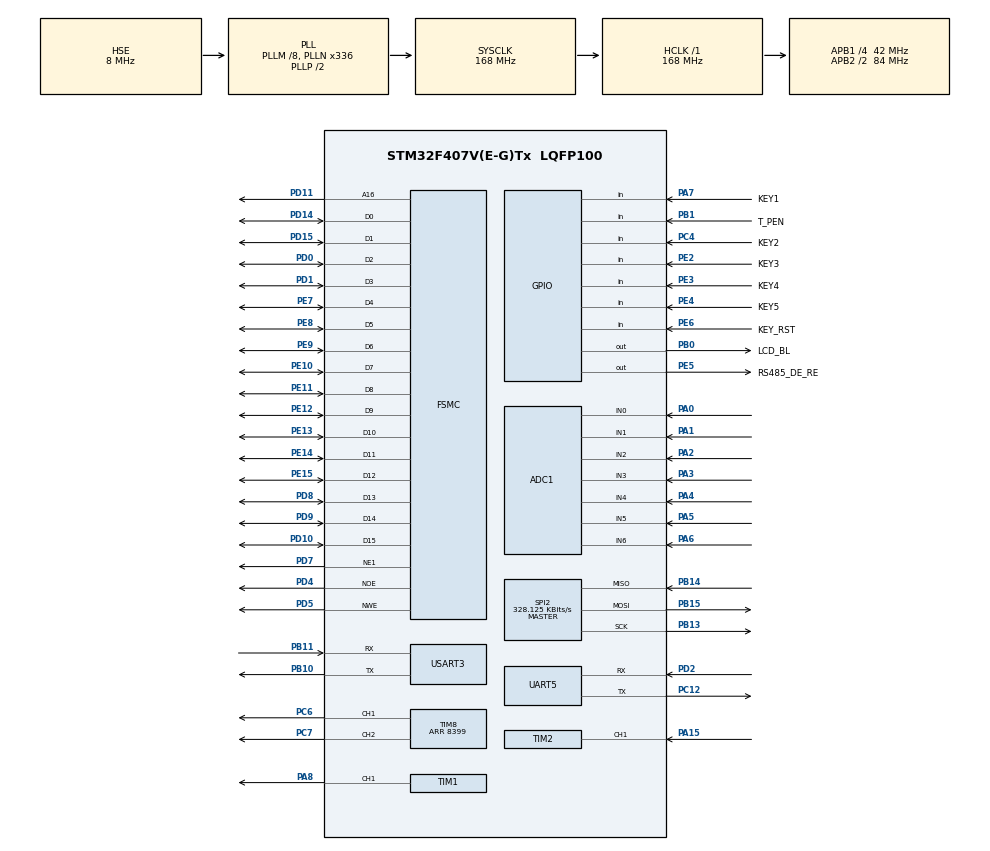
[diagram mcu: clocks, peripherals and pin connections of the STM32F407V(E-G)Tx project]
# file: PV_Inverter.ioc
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ADC1.Channel-12\#ChannelRegularConversion=ADC_CHANNEL_1
ADC1.Channel-13\#ChannelRegularConversion=ADC_CHANNEL_2
ADC1.Channel-14\#ChannelRegularConversion=ADC_CHANNEL_3
ADC1.Channel-15\#ChannelRegularConversion=ADC_CHANNEL_4
ADC1.Channel-16\#ChannelRegularConversion=ADC_CHANNEL_5
ADC1.Channel-17\#ChannelRegularConversion=ADC_CHANNEL_6
ADC1.ContinuousConvMode=ENABLE
ADC1.DMAContinuousRequests=ENABLE
ADC1.NbrOfConversion=7
ADC1.NbrOfConversionFlag=1
ADC1.Rank-12\#ChannelRegularConversion=2
ADC1.Rank-13\#ChannelRegularConversion=3
ADC1.Rank-14\#ChannelRegularConversion=4
ADC1.Rank-15\#ChannelRegularConversion=5
ADC1.Rank-16\#ChannelRegularConversion=6
ADC1.Rank-17\#ChannelRegularConversion=7
ADC1.SamplingTime-0\#ChannelRegularConversion=ADC_SAMPLETIME_480CYCLES
ADC1.SamplingTime-12\#ChannelRegularConversion=ADC_SAMPLETIME_480CYCLES
ADC1.SamplingTime-13\#ChannelRegularConversion=ADC_SAMPLETIME_480CYCLES
ADC1.SamplingTime-14\#ChannelRegularConversion=ADC_SAMPLETIME_144CYCLES
ADC1.SamplingTime-15\#ChannelRegularConversion=ADC_SAMPLETIME_144CYCLES
ADC1.SamplingTime-16\#ChannelRegularConversion=ADC_SAMPLETIME_480CYCLES
ADC1.SamplingTime-17\#ChannelRegularConversion=ADC_SAMPLETIME_480CYCLES
ADC1.ScanConvMode=ENABLE
ADC1.master=1
Dma.ADC1.0.Direction=DMA_PERIPH_TO_MEMORY
Dma.ADC1.0.FIFOMode=DMA_FIFOMODE_DISABLE
Dma.ADC1.0.Instance=DMA2_Stream0
Dma.ADC1.0.MemDataAlignment=DMA_MDATAALIGN_HALFWORD
Dma.ADC1.0.MemInc=DMA_MINC_ENABLE
Dma.ADC1.0.Mode=DMA_CIRCULAR
Dma.ADC1.0.PeriphDataAlignment=DMA_PDATAALIGN_HALFWORD
Dma.ADC1.0.PeriphInc=DMA_PINC_DISABLE
Dma.ADC1.0.Priority=DMA_PRIORITY_HIGH
Dma.Request0=ADC1
FREERTOS.Tasks01=defaultTask,24,128,StartDefaultTask,Default,NULL,Dynamic,NULL,NULL
FSMC.BusTurnAroundDuration1=0
FSMC.DataSetupTime1=15
IWDG.Prescaler=IWDG_PRESCALER_64
IWDG.Reload=1250
Mcu.Family=STM32F4
Mcu.Name=STM32F407V(E-G)Tx
Mcu.Package=LQFP100
NVIC.DMA2_Stream0_IRQn=true\:5\:0\:false\:false\:true\:true\:false\:true\:true
NVIC.PriorityGroup=NVIC_PRIORITYGROUP_4
NVIC.TIM6_DAC_IRQn=true\:15\:0\:false\:false\:true\:false\:false\:true\:true
NVIC.TimeBase=TIM6_DAC_IRQn
NVIC.TimeBaseIP=TIM6
NVIC.UART5_IRQn=true\:5\:0\:false\:false\:true\:true\:true\:true\:true
NVIC.USART3_IRQn=true\:5\:0\:false\:false\:true\:true\:true\:true\:true
PA0-WKUP.Signal=ADCx_IN0
PA1.Signal=ADCx_IN1
PA13.Mode=Serial_Wire
PA13.Signal=SYS_JTMS-SWDIO
PA14.Mode=Serial_Wire
PA14.Signal=SYS_JTCK-SWCLK
PA15.Signal=S_TIM2_CH1_ETR
PA2.Signal=ADCx_IN2
PA3.Signal=ADCx_IN3
PA4.Signal=ADCx_IN4
PA5.Signal=ADCx_IN5
PA6.Signal=ADCx_IN6
PA7.GPIO_Label=KEY1
PA7.GPIO_PuPd=GPIO_PULLUP
PA7.Signal=GPIO_Input
PA8.Signal=S_TIM1_CH1
PB0.GPIO_Label=LCD_BL
PB0.PinState=GPIO_PIN_SET
PB0.Signal=GPIO_Output
PB1.GPIO_Label=T_PEN
PB1.GPIO_PuPd=GPIO_PULLUP
PB1.Signal=GPIO_Input
PB10.Mode=Asynchronous
PB10.Signal=USART3_TX
PB11.Mode=Asynchronous
PB11.Signal=USART3_RX
PB12.Signal=SPI2_NSS
PB13.Mode=Full_Duplex_Master
PB13.Signal=SPI2_SCK
PB14.Mode=Full_Duplex_Master
PB14.Signal=SPI2_MISO
PB15.Mode=Full_Duplex_Master
PB15.Signal=SPI2_MOSI
PC12.Mode=Asynchronous
PC12.Signal=UART5_TX
PC4.GPIO_Label=KEY2
PC4.GPIO_PuPd=GPIO_PULLUP
PC4.Signal=GPIO_Input
PC6.Signal=S_TIM8_CH1
PC7.Signal=S_TIM8_CH2
PD0.Mode=16b-d1
PD0.Signal=FSMC_D2
PD1.Mode=16b-d1
PD1.Signal=FSMC_D3
PD10.Mode=16b-d1
PD10.Signal=FSMC_D15
PD11.Mode=A16_1
PD11.Signal=FSMC_A16
PD14.Mode=16b-d1
PD14.Signal=FSMC_D0
PD15.Mode=16b-d1
PD15.Signal=FSMC_D1
PD2.Mode=Asynchronous
PD2.Signal=UART5_RX
PD4.Mode=Lcd1
PD4.Signal=FSMC_NOE
PD5.Mode=Lcd1
PD5.Signal=FSMC_NWE
PD7.Mode=NorPsramChipSelect1_1
PD7.Signal=FSMC_NE1
PD8.Mode=16b-d1
PD8.Signal=FSMC_D13
PD9.Mode=16b-d1
PD9.Signal=FSMC_D14
PE10.Mode=16b-d1
PE10.Signal=FSMC_D7
PE11.Mode=16b-d1
PE11.Signal=FSMC_D8
PE12.Mode=16b-d1
PE12.Signal=FSMC_D9
PE13.Mode=16b-d1
PE13.Signal=FSMC_D10
PE14.Mode=16b-d1
PE14.Signal=FSMC_D11
PE15.Mode=16b-d1
PE15.Signal=FSMC_D12
PE2.GPIO_Label=KEY3
PE2.GPIO_PuPd=GPIO_PULLUP
PE2.Signal=GPIO_Input
PE3.GPIO_Label=KEY4
PE3.GPIO_PuPd=GPIO_PULLUP
PE3.Signal=GPIO_Input
PE4.GPIO_Label=KEY5
PE4.GPIO_PuPd=GPIO_PULLUP
PE4.Signal=GPIO_Input
PE5.GPIO_Label=RS485_DE_RE
PE5.Signal=GPIO_Output
PE6.GPIO_Label=KEY_RST
PE6.GPIO_PuPd=GPIO_PULLUP
PE6.Signal=GPIO_Input
PE7.Mode=16b-d1
PE7.Signal=FSMC_D4
PE8.Mode=16b-d1
PE8.Signal=FSMC_D5
PE9.Mode=16b-d1
PE9.Signal=FSMC_D6
PH0-OSC_IN.Mode=HSE-External-Oscillator
PH0-OSC_IN.Signal=RCC_OSC_IN
PH1-OSC_OUT.Mode=HSE-External-Oscillator
PH1-OSC_OUT.Signal=RCC_OSC_OUT
ProjectManager.HeapSize=0x200
ProjectManager.StackSize=0x400
ProjectManager.TargetToolchain=MDK-ARM V5.32
RCC.48MHZClocksFreq_Value=84000000
RCC.AHBFreq_Value=168000000
RCC.APB1CLKDivider=RCC_HCLK_DIV4
RCC.APB1Freq_Value=42000000
RCC.APB1TimFreq_Value=84000000
RCC.APB2CLKDivider=RCC_HCLK_DIV2
RCC.APB2Freq_Value=84000000
RCC.APB2TimFreq_Value=168000000
RCC.CortexFreq_Value=168000000
RCC.HCLKFreq_Value=168000000
RCC.HSE_VALUE=8000000
RCC.HSI_VALUE=16000000
RCC.LSE_VALUE=32768
RCC.PLLM=8
RCC.PLLN=336
RCC.PLLSourceVirtual=RCC_PLLSOURCE_HSE
RCC.SYSCLKFreq_VALUE=168000000
RCC.SYSCLKSource=RCC_SYSCLKSOURCE_PLLCLK
RCC.VCOOutputFreq_Value=336000000
SH.ADCx_IN0.0=ADC1_IN0,IN0
SH.ADCx_IN1.0=ADC1_IN1,IN1
SH.ADCx_IN2.0=ADC1_IN2,IN2
SH.ADCx_IN3.0=ADC1_IN3,IN3
SH.ADCx_IN4.0=ADC1_IN4,IN4
SH.ADCx_IN5.0=ADC1_IN5,IN5
SH.ADCx_IN6.0=ADC1_IN6,IN6
SH.S_TIM1_CH1.0=TIM1_CH1,PWM Generation1 CH1
SH.S_TIM2_CH1_ETR.0=TIM2_CH1,Input_Capture1_from_TI1
SH.S_TIM8_CH1.0=TIM8_CH1,PWM Generation1 CH1
SH.S_TIM8_CH2.0=TIM8_CH2,PWM Generation2 CH2
SPI2.BaudRatePrescaler=SPI_BAUDRATEPRESCALER_128
SPI2.CalculateBaudRate=328.125 KBits/s
SPI2.Direction=SPI_DIRECTION_2LINES
SPI2.Mode=SPI_MODE_MASTER
SPI2.VirtualType=VM_MASTER
TIM1.AutoReloadPreload=TIM_AUTORELOAD_PRELOAD_ENABLE
TIM1.Channel-PWM\ Generation1\ CH1=TIM_CHANNEL_1
TIM1.Period=8399
TIM2.Channel-Input_Capture1_from_TI1=TIM_CHANNEL_1
TIM2.ICFilter_CH1=8
TIM2.Period=65535
TIM2.Prescaler=167
TIM8.AutoReloadPreload=TIM_AUTORELOAD_PRELOAD_ENABLE
TIM8.AutomaticOutput=TIM_AUTOMATICOUTPUT_DISABLE
TIM8.BreakState=TIM_BREAK_DISABLE
TIM8.Channel-PWM\ Generation1\ CH1=TIM_CHANNEL_1
TIM8.Channel-PWM\ Generation2\ CH2=TIM_CHANNEL_2
TIM8.CounterMode=TIM_COUNTERMODE_CENTERALIGNED1
TIM8.OffStateIDLEMode=TIM_OSSI_DISABLE
TIM8.OffStateRunMode=TIM_OSSR_DISABLE
TIM8.Period=8399
UART5.VirtualMode=Asynchronous
USART3.VirtualMode=VM_ASYNC
VP_FREERTOS_VS_CMSIS_V2.Mode=CMSIS_V2
VP_IWDG_VS_IWDG.Mode=IWDG_Activate
VP_SYS_VS_tim6.Mode=TIM6
board=custom

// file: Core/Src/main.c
/* USER CODE BEGIN Header */
/**
  ******************************************************************************
  * @file           : main.c
  * @brief          : Main program body
  ******************************************************************************
  * @attention
  *
  * Copyright (c) 2026 STMicroelectronics.
  * All rights reserved.
  *
  * This software is licensed under terms that can be found in the LICENSE file
  * in the root directory of this software component.
  * If no LICENSE file comes with this software, it is provided AS-IS.
  *
  ******************************************************************************
  */
/* USER CODE END Header */
#include "main.h"
#include "cmsis_os.h"
#include "adc.h"
#include "dma.h"
#include "iwdg.h"
#include "spi.h"
#include "tim.h"
#include "usart.h"
#include "gpio.h"
#include "fsmc.h"
#include "spwm.h"

void SystemClock_Config(void);
void MX_FREERTOS_Init(void);

int main(void)
{

  /* MCU Configuration--------------------------------------------------------*/

  /* Reset of all peripherals, Initializes the Flash interface and the Systick. */
  HAL_Init();

  /* Configure the system clock */
  SystemClock_Config();

  /* Initialize all configured peripherals */
  MX_GPIO_Init();
  MX_DMA_Init();
  MX_ADC1_Init();
  MX_TIM1_Init();
  MX_TIM2_Init();
  MX_TIM8_Init();
  MX_USART3_UART_Init();
  MX_FSMC_Init();
  MX_IWDG_Init();
  MX_SPI2_Init();
  MX_UART5_Init();

  /* Init scheduler */
  osKernelInitialize();  /* Call init function for freertos objects (in cmsis_os2.c) */
  MX_FREERTOS_Init();

  /* Start scheduler */
  osKernelStart();

  /* We should never get here as control is now taken by the scheduler */

  /* Infinite loop */
  while (1)
  {

  }
}

void SystemClock_Config(void)
{
  RCC_OscInitTypeDef RCC_OscInitStruct = {0};
  RCC_ClkInitTypeDef RCC_ClkInitStruct = {0};

  /** Configure the main internal regulator output voltage
  */
  __HAL_RCC_PWR_CLK_ENABLE();
  __HAL_PWR_VOLTAGESCALING_CONFIG(PWR_REGULATOR_VOLTAGE_SCALE1);

  /** Initializes the RCC Oscillators according to the specified parameters
  * in the RCC_OscInitTypeDef structure.
  */
  RCC_OscInitStruct.OscillatorType = RCC_OSCILLATORTYPE_LSI|RCC_OSCILLATORTYPE_HSE;
  RCC_OscInitStruct.HSEState = RCC_HSE_ON;
  RCC_OscInitStruct.LSIState = RCC_LSI_ON;
  RCC_OscInitStruct.PLL.PLLState = RCC_PLL_ON;
  RCC_OscInitStruct.PLL.PLLSource = RCC_PLLSOURCE_HSE;
  RCC_OscInitStruct.PLL.PLLM = 8;
  RCC_OscInitStruct.PLL.PLLN = 336;
  RCC_OscInitStruct.PLL.PLLP = RCC_PLLP_DIV2;
  RCC_OscInitStruct.PLL.PLLQ = 4;
  if (HAL_RCC_OscConfig(&RCC_OscInitStruct) != HAL_OK)
  {
    Error_Handler();
  }

  /** Initializes the CPU, AHB and APB buses clocks
  */
  RCC_ClkInitStruct.ClockType = RCC_CLOCKTYPE_HCLK|RCC_CLOCKTYPE_SYSCLK
                              |RCC_CLOCKTYPE_PCLK1|RCC_CLOCKTYPE_PCLK2;
  RCC_ClkInitStruct.SYSCLKSource = RCC_SYSCLKSOURCE_PLLCLK;
  RCC_ClkInitStruct.AHBCLKDivider = RCC_SYSCLK_DIV1;
  RCC_ClkInitStruct.APB1CLKDivider = RCC_HCLK_DIV4;
  RCC_ClkInitStruct.APB2CLKDivider = RCC_HCLK_DIV2;

  if (HAL_RCC_ClockConfig(&RCC_ClkInitStruct, FLASH_LATENCY_5) != HAL_OK)
  {
    Error_Handler();
  }
}

void HAL_TIM_PeriodElapsedCallback(TIM_HandleTypeDef *htim)
{
  if (htim->Instance == TIM6)
  {
    HAL_IncTick();
  }
  else if (htim == &htim8)
  {
    SPWM_Update();
  }
}

void Error_Handler(void)
{
  __disable_irq();
  while (1)
  {
  }
}

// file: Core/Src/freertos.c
/* USER CODE BEGIN Header */
/**
  ******************************************************************************
  * File Name          : freertos.c
  * Description        : Code for freertos applications
  ******************************************************************************
  * @attention
  *
  * Copyright (c) 2026 STMicroelectronics.
  * All rights reserved.
  *
  * This software is licensed under terms that can be found in the LICENSE file
  * in the root directory of this software component.
  * If no LICENSE file comes with this software, it is provided AS-IS.
  *
  ******************************************************************************
  */
/* USER CODE END Header */

#include "FreeRTOS.h"
#include "app_task.h"
#include "main.h"
#include "cmsis_os.h"

/* USER CODE BEGIN Includes */
#include "app_task.h"
/* USER CODE END Includes */

/* Definitions for defaultTask */

void MX_FREERTOS_Init(void); /* (MISRA C 2004 rule 8.1) */

void MX_FREERTOS_Init(void) {

  /* Create the thread(s) */
  /* creation of defaultTask */

  /* USER CODE BEGIN RTOS_THREADS */
  /* 创建自定义初始化任务 (替代defaultTask) */
  Create_InitTask();
  /* USER CODE END RTOS_THREADS */

}
